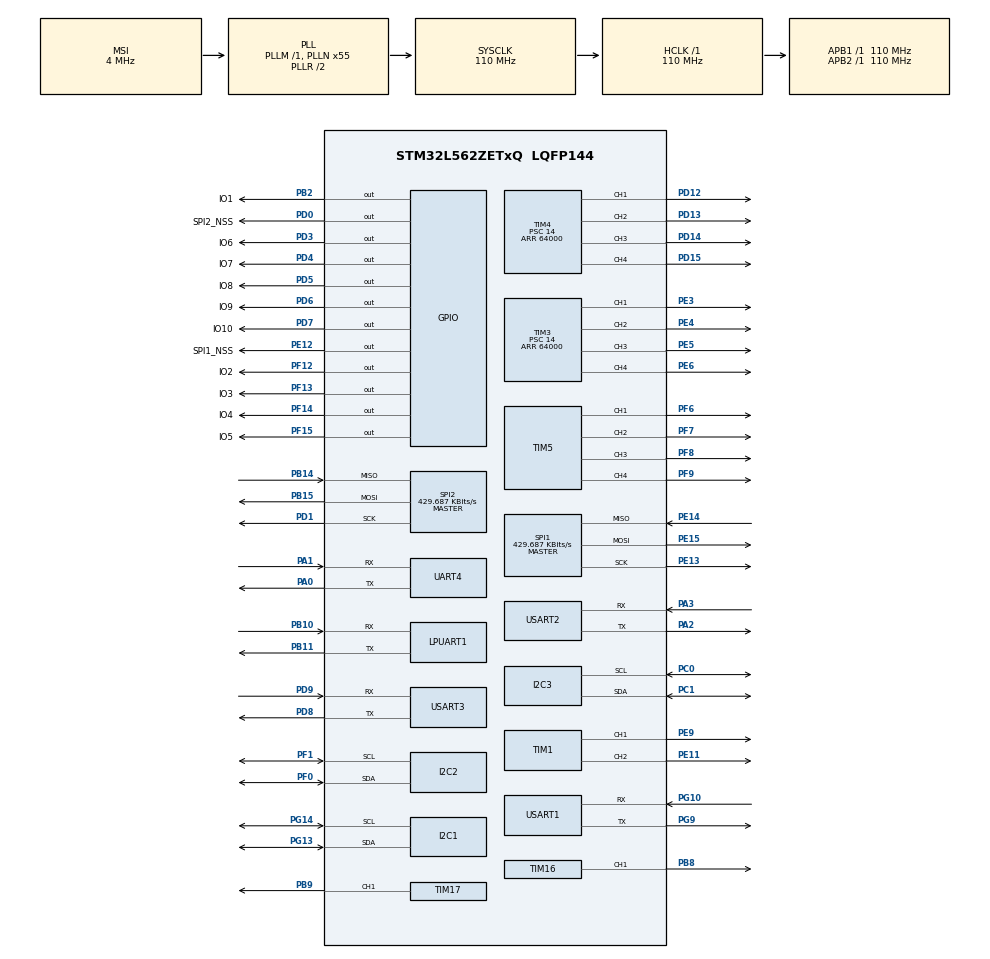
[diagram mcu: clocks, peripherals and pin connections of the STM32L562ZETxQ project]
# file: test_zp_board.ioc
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I2C1.Timing=0x60514452
I2C2.Timing=0x60514452
I2C3.Timing=0x60514452
Mcu.Family=STM32L5
Mcu.Name=STM32L562ZETxQ
Mcu.Package=LQFP144
NVIC.PriorityGroup=NVIC_PRIORITYGROUP_3
PA0.Mode=Asynchronous
PA0.Signal=UART4_TX
PA1.Mode=Asynchronous
PA1.Signal=UART4_RX
PA13\ (JTMS/SWDIO).Mode=Trace_Asynchronous_SW
PA13\ (JTMS/SWDIO).Signal=DEBUG_JTMS-SWDIO
PA14\ (JTCK/SWCLK).Mode=Trace_Asynchronous_SW
PA14\ (JTCK/SWCLK).Signal=DEBUG_JTCK-SWCLK
PA2.Mode=Asynchronous
PA2.Signal=USART2_TX
PA3.Mode=Asynchronous
PA3.Signal=USART2_RX
PB10.Mode=Asynchronous
PB10.Signal=LPUART1_RX
PB11.Mode=Asynchronous
PB11.Signal=LPUART1_TX
PB14.Mode=Full_Duplex_Master
PB14.Signal=SPI2_MISO
PB15.Mode=Full_Duplex_Master
PB15.Signal=SPI2_MOSI
PB2.GPIO_Label=IO1
PB2.PinState=GPIO_PIN_RESET
PB2.Signal=GPIO_Output
PB3\ (JTDO/TRACESWO).Mode=Trace_Asynchronous_SW
PB3\ (JTDO/TRACESWO).Signal=DEBUG_JTDO-SWO
PB8.Signal=S_TIM16_CH1
PB9.Signal=S_TIM17_CH1
PC0.Mode=I2C
PC0.Signal=I2C3_SCL
PC1.Mode=I2C
PC1.Signal=I2C3_SDA
PD0.GPIO_Label=SPI2_NSS
PD0.PinState=GPIO_PIN_SET
PD0.Signal=GPIO_Output
PD1.Mode=Full_Duplex_Master
PD1.Signal=SPI2_SCK
PD12.Signal=S_TIM4_CH1
PD13.Signal=S_TIM4_CH2
PD14.Signal=S_TIM4_CH3
PD15.Signal=S_TIM4_CH4
PD3.GPIO_Label=IO6
PD3.Signal=GPIO_Output
PD4.GPIO_Label=IO7
PD4.Signal=GPIO_Output
PD5.GPIO_Label=IO8
PD5.Signal=GPIO_Output
PD6.GPIO_Label=IO9
PD6.Signal=GPIO_Output
PD7.GPIO_Label=IO10
PD7.Signal=GPIO_Output
PD8.Mode=Asynchronous
PD8.Signal=USART3_TX
PD9.Mode=Asynchronous
PD9.Signal=USART3_RX
PE11.Signal=S_TIM1_CH2
PE12.GPIO_Label=SPI1_NSS
PE12.PinState=GPIO_PIN_SET
PE12.Signal=GPIO_Output
PE13.Mode=Full_Duplex_Master
PE13.Signal=SPI1_SCK
PE14.Mode=Full_Duplex_Master
PE14.Signal=SPI1_MISO
PE15.Mode=Full_Duplex_Master
PE15.Signal=SPI1_MOSI
PE3.Signal=S_TIM3_CH1
PE4.Signal=S_TIM3_CH2
PE5.Signal=S_TIM3_CH3
PE6.Signal=S_TIM3_CH4
PE9.Signal=S_TIM1_CH1
PF0.Mode=I2C
PF0.Signal=I2C2_SDA
PF1.Mode=I2C
PF1.Signal=I2C2_SCL
PF12.GPIO_Label=IO2
PF12.Signal=GPIO_Output
PF13.GPIO_Label=IO3
PF13.GPIO_ModeDefaultOutputPP=GPIO_MODE_OUTPUT_PP
PF13.GPIO_Speed=GPIO_SPEED_FREQ_LOW
PF13.Signal=GPIO_Output
PF14.GPIO_Label=IO4
PF14.Signal=GPIO_Output
PF15.GPIO_Label=IO5
PF15.Signal=GPIO_Output
PF6.Signal=S_TIM5_CH1
PF7.Signal=S_TIM5_CH2
PF8.Signal=S_TIM5_CH3
PF9.Signal=S_TIM5_CH4
PG10.Mode=Asynchronous
PG10.Signal=USART1_RX
PG13.Mode=I2C
PG13.Signal=I2C1_SDA
PG14.Mode=I2C
PG14.Signal=I2C1_SCL
PG9.Mode=Asynchronous
PG9.Signal=USART1_TX
PH0-OSC_IN\ (PH0).Mode=HSE-External-Oscillator
PH0-OSC_IN\ (PH0).Signal=RCC_OSC_IN
PH1-OSC_OUT\ (PH1).Mode=HSE-External-Oscillator
PH1-OSC_OUT\ (PH1).Signal=RCC_OSC_OUT
ProjectManager.HeapSize=0x200
ProjectManager.StackSize=0x400
ProjectManager.TargetToolchain=STM32CubeIDE
RCC.AHBFreq_Value=110000000
RCC.APB1Freq_Value=110000000
RCC.APB1TimFreq_Value=110000000
RCC.APB2Freq_Value=110000000
RCC.APB2TimFreq_Value=110000000
RCC.CortexFreq_Value=110000000
RCC.HCLKFreq_Value=110000000
RCC.HSE_VALUE=16000000
RCC.HSI48_VALUE=48000000
RCC.HSI_VALUE=16000000
RCC.LSE_VALUE=32768
RCC.MSI_VALUE=4000000
RCC.PLLN=55
RCC.SYSCLKFreq_VALUE=110000000
RCC.SYSCLKSource=RCC_SYSCLKSOURCE_PLLCLK
RCC.VCOOutputFreq_Value=220000000
SH.S_TIM16_CH1.0=TIM16_CH1,PWM Generation1 CH1
SH.S_TIM17_CH1.0=TIM17_CH1,PWM Generation1 CH1
SH.S_TIM1_CH1.0=TIM1_CH1,PWM Generation1 CH1
SH.S_TIM1_CH2.0=TIM1_CH2,PWM Generation2 CH2
SH.S_TIM3_CH1.0=TIM3_CH1,PWM Generation1 CH1
SH.S_TIM3_CH2.0=TIM3_CH2,PWM Generation2 CH2
SH.S_TIM3_CH3.0=TIM3_CH3,PWM Generation3 CH3
SH.S_TIM3_CH4.0=TIM3_CH4,PWM Generation4 CH4
SH.S_TIM4_CH1.0=TIM4_CH1,PWM Generation1 CH1
SH.S_TIM4_CH2.0=TIM4_CH2,PWM Generation2 CH2
SH.S_TIM4_CH3.0=TIM4_CH3,PWM Generation3 CH3
SH.S_TIM4_CH4.0=TIM4_CH4,PWM Generation4 CH4
SH.S_TIM5_CH1.0=TIM5_CH1,PWM Generation1 CH1
SH.S_TIM5_CH2.0=TIM5_CH2,PWM Generation2 CH2
SH.S_TIM5_CH3.0=TIM5_CH3,PWM Generation3 CH3
SH.S_TIM5_CH4.0=TIM5_CH4,Forced Output4 CH4
SPI1.BaudRatePrescaler=SPI_BAUDRATEPRESCALER_256
SPI1.CalculateBaudRate=429.687 KBits/s
SPI1.DataSize=SPI_DATASIZE_8BIT
SPI1.Direction=SPI_DIRECTION_2LINES
SPI1.Mode=SPI_MODE_MASTER
SPI1.VirtualType=VM_MASTER
SPI2.BaudRatePrescaler=SPI_BAUDRATEPRESCALER_256
SPI2.CalculateBaudRate=429.687 KBits/s
SPI2.DataSize=SPI_DATASIZE_8BIT
SPI2.Direction=SPI_DIRECTION_2LINES
SPI2.Mode=SPI_MODE_MASTER
SPI2.VirtualType=VM_MASTER
TIM1.Channel-PWM\ Generation1\ CH1=TIM_CHANNEL_1
TIM1.Channel-PWM\ Generation2\ CH2=TIM_CHANNEL_2
TIM16.Channel=TIM_CHANNEL_1
TIM17.Channel=TIM_CHANNEL_1
TIM3.Channel-PWM\ Generation1\ CH1=TIM_CHANNEL_1
TIM3.Channel-PWM\ Generation2\ CH2=TIM_CHANNEL_2
TIM3.Channel-PWM\ Generation3\ CH3=TIM_CHANNEL_3
TIM3.Channel-PWM\ Generation4\ CH4=TIM_CHANNEL_4
TIM3.Period=64000
TIM3.Prescaler=14
TIM4.Channel-PWM\ Generation1\ CH1=TIM_CHANNEL_1
TIM4.Channel-PWM\ Generation2\ CH2=TIM_CHANNEL_2
TIM4.Channel-PWM\ Generation3\ CH3=TIM_CHANNEL_3
TIM4.Channel-PWM\ Generation4\ CH4=TIM_CHANNEL_4
TIM4.Period=64000
TIM4.Prescaler=14
TIM5.Channel-Forced\ Output4\ CH4=TIM_CHANNEL_4
TIM5.Channel-PWM\ Generation1\ CH1=TIM_CHANNEL_1
TIM5.Channel-PWM\ Generation2\ CH2=TIM_CHANNEL_2
TIM5.Channel-PWM\ Generation3\ CH3=TIM_CHANNEL_3
USART1.VirtualMode-Asynchronous=VM_ASYNC
USART2.VirtualMode-Asynchronous=VM_ASYNC
USART3.VirtualMode-Asynchronous=VM_ASYNC
VP_PWR_VS_DBSignals.Mode=DisableDeadBatterySignals
VP_PWR_VS_SECSignals.Mode=Security/Privilege
VP_TIM16_VS_ClockSourceINT.Mode=Enable_Timer
VP_TIM17_VS_ClockSourceINT.Mode=Enable_Timer
VP_TIM1_VS_ClockSourceINT.Mode=Internal
VP_TIM3_VS_ClockSourceINT.Mode=Internal
VP_TIM4_VS_ClockSourceINT.Mode=Internal
VP_TIM5_VS_ClockSourceINT.Mode=Internal
board=custom

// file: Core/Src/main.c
/* USER CODE BEGIN Header */
/**
  ******************************************************************************
  * @file           : main.c
  * @brief          : Main program body
  ******************************************************************************
  * @attention
  *
  * Copyright (c) 2025 STMicroelectronics.
  * All rights reserved.
  *
  * This software is licensed under terms that can be found in the LICENSE file
  * in the root directory of this software component.
  * If no LICENSE file comes with this software, it is provided AS-IS.
  *
  ******************************************************************************
  */
/* USER CODE END Header */
#include "main.h"

/* USER CODE BEGIN Includes */
#include <stdio.h>
#include "test.h"
/* USER CODE END Includes */

I2C_HandleTypeDef hi2c1;
I2C_HandleTypeDef hi2c2;
I2C_HandleTypeDef hi2c3;

UART_HandleTypeDef hlpuart1;
UART_HandleTypeDef huart4;
UART_HandleTypeDef huart1;
UART_HandleTypeDef huart2;
UART_HandleTypeDef huart3;

SPI_HandleTypeDef hspi1;
SPI_HandleTypeDef hspi2;

TIM_HandleTypeDef htim1;
TIM_HandleTypeDef htim3;
TIM_HandleTypeDef htim4;
TIM_HandleTypeDef htim5;
TIM_HandleTypeDef htim16;
TIM_HandleTypeDef htim17;

void SystemClock_Config(void);
static void MX_GPIO_Init(void);
static void MX_TIM4_Init(void);
static void MX_TIM3_Init(void);
static void MX_SPI1_Init(void);
static void MX_SPI2_Init(void);
static void MX_I2C1_Init(void);
static void MX_I2C2_Init(void);
static void MX_I2C3_Init(void);
static void MX_UART4_Init(void);
static void MX_USART1_UART_Init(void);
static void MX_TIM1_Init(void);
static void MX_TIM5_Init(void);
static void MX_TIM16_Init(void);
static void MX_TIM17_Init(void);
static void MX_LPUART1_UART_Init(void);
static void MX_USART2_UART_Init(void);
static void MX_USART3_UART_Init(void);

int main(void)
{

  /* USER CODE BEGIN 1 */
  //uint32_t min_reload = __HAL_TIM_GET_AUTORELOAD(&htim4) * 0.05;
  /* USER CODE END 1 */

  /* MCU Configuration--------------------------------------------------------*/

  /* Reset of all peripherals, Initializes the Flash interface and the Systick. */
  HAL_Init();

  /* Configure the system clock */
  SystemClock_Config();

  /* Initialize all configured peripherals */
  MX_GPIO_Init();
  MX_TIM4_Init();
  MX_TIM3_Init();
  MX_SPI1_Init();
  MX_SPI2_Init();
  MX_I2C1_Init();
  MX_I2C2_Init();
  MX_I2C3_Init();
  MX_UART4_Init();
  MX_USART1_UART_Init();
  MX_TIM1_Init();
  MX_TIM5_Init();
  MX_TIM16_Init();
  MX_TIM17_Init();
  MX_LPUART1_UART_Init();
  MX_USART2_UART_Init();
  MX_USART3_UART_Init();
  /* USER CODE BEGIN 2 */
  //testGPIO();             //GPIO Testing
  //testTimers();           //Timer Testing
  /* USER CODE END 2 */

  /* Infinite loop */
  /* USER CODE BEGIN WHILE */
  while (1)
  {
    //testI2CTx(&hi2c1);    //I2C Testing (Transmit)
    //testI2CRx(&hi2c1);    //I2C Testing (Receive)
    //testSPI(&hspi2);      //SPI Testing
    testUART(&huart4);    //UART Testing
    HAL_Delay(1000);
    /* USER CODE END WHILE */

  }
}

void SystemClock_Config(void)
{
  RCC_OscInitTypeDef RCC_OscInitStruct = {0};
  RCC_ClkInitTypeDef RCC_ClkInitStruct = {0};

  /** Configure the main internal regulator output voltage
  */
  if (HAL_PWREx_ControlVoltageScaling(PWR_REGULATOR_VOLTAGE_SCALE0) != HAL_OK)
  {
    Error_Handler();
  }

  /** Initializes the RCC Oscillators according to the specified parameters
  * in the RCC_OscInitTypeDef structure.
  */
  RCC_OscInitStruct.OscillatorType = RCC_OSCILLATORTYPE_MSI;
  RCC_OscInitStruct.MSIState = RCC_MSI_ON;
  RCC_OscInitStruct.MSICalibrationValue = RCC_MSICALIBRATION_DEFAULT;
  RCC_OscInitStruct.MSIClockRange = RCC_MSIRANGE_6;
  RCC_OscInitStruct.PLL.PLLState = RCC_PLL_ON;
  RCC_OscInitStruct.PLL.PLLSource = RCC_PLLSOURCE_MSI;
  RCC_OscInitStruct.PLL.PLLM = 1;
  RCC_OscInitStruct.PLL.PLLN = 55;
  RCC_OscInitStruct.PLL.PLLP = RCC_PLLP_DIV7;
  RCC_OscInitStruct.PLL.PLLQ = RCC_PLLQ_DIV2;
  RCC_OscInitStruct.PLL.PLLR = RCC_PLLR_DIV2;
  if (HAL_RCC_OscConfig(&RCC_OscInitStruct) != HAL_OK)
  {
    Error_Handler();
  }

  /** Initializes the CPU, AHB and APB buses clocks
  */
  RCC_ClkInitStruct.ClockType = RCC_CLOCKTYPE_HCLK|RCC_CLOCKTYPE_SYSCLK
                              |RCC_CLOCKTYPE_PCLK1|RCC_CLOCKTYPE_PCLK2;
  RCC_ClkInitStruct.SYSCLKSource = RCC_SYSCLKSOURCE_PLLCLK;
  RCC_ClkInitStruct.AHBCLKDivider = RCC_SYSCLK_DIV1;
  RCC_ClkInitStruct.APB1CLKDivider = RCC_HCLK_DIV1;
  RCC_ClkInitStruct.APB2CLKDivider = RCC_HCLK_DIV1;

  if (HAL_RCC_ClockConfig(&RCC_ClkInitStruct, FLASH_LATENCY_5) != HAL_OK)
  {
    Error_Handler();
  }
}

static void MX_I2C1_Init(void)
{

  hi2c1.Instance = I2C1;
  hi2c1.Init.Timing = 0x60514452;
  hi2c1.Init.OwnAddress1 = 0;
  hi2c1.Init.AddressingMode = I2C_ADDRESSINGMODE_7BIT;
  hi2c1.Init.DualAddressMode = I2C_DUALADDRESS_DISABLE;
  hi2c1.Init.OwnAddress2 = 0;
  hi2c1.Init.OwnAddress2Masks = I2C_OA2_NOMASK;
  hi2c1.Init.GeneralCallMode = I2C_GENERALCALL_DISABLE;
  hi2c1.Init.NoStretchMode = I2C_NOSTRETCH_DISABLE;
  if (HAL_I2C_Init(&hi2c1) != HAL_OK)
  {
    Error_Handler();
  }

  /** Configure Analogue filter
  */
  if (HAL_I2CEx_ConfigAnalogFilter(&hi2c1, I2C_ANALOGFILTER_ENABLE) != HAL_OK)
  {
    Error_Handler();
  }

  /** Configure Digital filter
  */
  if (HAL_I2CEx_ConfigDigitalFilter(&hi2c1, 0) != HAL_OK)
  {
    Error_Handler();
  }

}

static void MX_I2C2_Init(void)
{

  hi2c2.Instance = I2C2;
  hi2c2.Init.Timing = 0x60514452;
  hi2c2.Init.OwnAddress1 = 0;
  hi2c2.Init.AddressingMode = I2C_ADDRESSINGMODE_7BIT;
  hi2c2.Init.DualAddressMode = I2C_DUALADDRESS_DISABLE;
  hi2c2.Init.OwnAddress2 = 0;
  hi2c2.Init.OwnAddress2Masks = I2C_OA2_NOMASK;
  hi2c2.Init.GeneralCallMode = I2C_GENERALCALL_DISABLE;
  hi2c2.Init.NoStretchMode = I2C_NOSTRETCH_DISABLE;
  if (HAL_I2C_Init(&hi2c2) != HAL_OK)
  {
    Error_Handler();
  }

  /** Configure Analogue filter
  */
  if (HAL_I2CEx_ConfigAnalogFilter(&hi2c2, I2C_ANALOGFILTER_ENABLE) != HAL_OK)
  {
    Error_Handler();
  }

  /** Configure Digital filter
  */
  if (HAL_I2CEx_ConfigDigitalFilter(&hi2c2, 0) != HAL_OK)
  {
    Error_Handler();
  }

}

static void MX_I2C3_Init(void)
{

  hi2c3.Instance = I2C3;
  hi2c3.Init.Timing = 0x60514452;
  hi2c3.Init.OwnAddress1 = 0;
  hi2c3.Init.AddressingMode = I2C_ADDRESSINGMODE_7BIT;
  hi2c3.Init.DualAddressMode = I2C_DUALADDRESS_DISABLE;
  hi2c3.Init.OwnAddress2 = 0;
  hi2c3.Init.OwnAddress2Masks = I2C_OA2_NOMASK;
  hi2c3.Init.GeneralCallMode = I2C_GENERALCALL_DISABLE;
  hi2c3.Init.NoStretchMode = I2C_NOSTRETCH_DISABLE;
  if (HAL_I2C_Init(&hi2c3) != HAL_OK)
  {
    Error_Handler();
  }

  /** Configure Analogue filter
  */
  if (HAL_I2CEx_ConfigAnalogFilter(&hi2c3, I2C_ANALOGFILTER_ENABLE) != HAL_OK)
  {
    Error_Handler();
  }

  /** Configure Digital filter
  */
  if (HAL_I2CEx_ConfigDigitalFilter(&hi2c3, 0) != HAL_OK)
  {
    Error_Handler();
  }

}

static void MX_LPUART1_UART_Init(void)
{

  hlpuart1.Instance = LPUART1;
  hlpuart1.Init.BaudRate = 209700;
  hlpuart1.Init.WordLength = UART_WORDLENGTH_8B;
  hlpuart1.Init.StopBits = UART_STOPBITS_1;
  hlpuart1.Init.Parity = UART_PARITY_NONE;
  hlpuart1.Init.Mode = UART_MODE_TX_RX;
  hlpuart1.Init.HwFlowCtl = UART_HWCONTROL_NONE;
  hlpuart1.Init.OneBitSampling = UART_ONE_BIT_SAMPLE_DISABLE;
  hlpuart1.Init.ClockPrescaler = UART_PRESCALER_DIV1;
  hlpuart1.AdvancedInit.AdvFeatureInit = UART_ADVFEATURE_NO_INIT;
  hlpuart1.FifoMode = UART_FIFOMODE_DISABLE;
  if (HAL_UART_Init(&hlpuart1) != HAL_OK)
  {
    Error_Handler();
  }
  if (HAL_UARTEx_SetTxFifoThreshold(&hlpuart1, UART_TXFIFO_THRESHOLD_1_8) != HAL_OK)
  {
    Error_Handler();
  }
  if (HAL_UARTEx_SetRxFifoThreshold(&hlpuart1, UART_RXFIFO_THRESHOLD_1_8) != HAL_OK)
  {
    Error_Handler();
  }
  if (HAL_UARTEx_DisableFifoMode(&hlpuart1) != HAL_OK)
  {
    Error_Handler();
  }

}

static void MX_UART4_Init(void)
{

  huart4.Instance = UART4;
  huart4.Init.BaudRate = 115200;
  huart4.Init.WordLength = UART_WORDLENGTH_8B;
  huart4.Init.StopBits = UART_STOPBITS_1;
  huart4.Init.Parity = UART_PARITY_NONE;
  huart4.Init.Mode = UART_MODE_TX_RX;
  huart4.Init.HwFlowCtl = UART_HWCONTROL_NONE;
  huart4.Init.OverSampling = UART_OVERSAMPLING_16;
  huart4.Init.OneBitSampling = UART_ONE_BIT_SAMPLE_DISABLE;
  huart4.Init.ClockPrescaler = UART_PRESCALER_DIV1;
  huart4.AdvancedInit.AdvFeatureInit = UART_ADVFEATURE_NO_INIT;
  if (HAL_UART_Init(&huart4) != HAL_OK)
  {
    Error_Handler();
  }
  if (HAL_UARTEx_SetTxFifoThreshold(&huart4, UART_TXFIFO_THRESHOLD_1_8) != HAL_OK)
  {
    Error_Handler();
  }
  if (HAL_UARTEx_SetRxFifoThreshold(&huart4, UART_RXFIFO_THRESHOLD_1_8) != HAL_OK)
  {
    Error_Handler();
  }
  if (HAL_UARTEx_DisableFifoMode(&huart4) != HAL_OK)
  {
    Error_Handler();
  }

}

static void MX_USART1_UART_Init(void)
{

  huart1.Instance = USART1;
  huart1.Init.BaudRate = 115200;
  huart1.Init.WordLength = UART_WORDLENGTH_8B;
  huart1.Init.StopBits = UART_STOPBITS_1;
  huart1.Init.Parity = UART_PARITY_NONE;
  huart1.Init.Mode = UART_MODE_TX_RX;
  huart1.Init.HwFlowCtl = UART_HWCONTROL_NONE;
  huart1.Init.OverSampling = UART_OVERSAMPLING_16;
  huart1.Init.OneBitSampling = UART_ONE_BIT_SAMPLE_DISABLE;
  huart1.Init.ClockPrescaler = UART_PRESCALER_DIV1;
  huart1.AdvancedInit.AdvFeatureInit = UART_ADVFEATURE_NO_INIT;
  if (HAL_UART_Init(&huart1) != HAL_OK)
  {
    Error_Handler();
  }
  if (HAL_UARTEx_SetTxFifoThreshold(&huart1, UART_TXFIFO_THRESHOLD_1_8) != HAL_OK)
  {
    Error_Handler();
  }
  if (HAL_UARTEx_SetRxFifoThreshold(&huart1, UART_RXFIFO_THRESHOLD_1_8) != HAL_OK)
  {
    Error_Handler();
  }
  if (HAL_UARTEx_DisableFifoMode(&huart1) != HAL_OK)
  {
    Error_Handler();
  }

}

static void MX_USART2_UART_Init(void)
{

  huart2.Instance = USART2;
  huart2.Init.BaudRate = 115200;
  huart2.Init.WordLength = UART_WORDLENGTH_8B;
  huart2.Init.StopBits = UART_STOPBITS_1;
  huart2.Init.Parity = UART_PARITY_NONE;
  huart2.Init.Mode = UART_MODE_TX_RX;
  huart2.Init.HwFlowCtl = UART_HWCONTROL_NONE;
  huart2.Init.OverSampling = UART_OVERSAMPLING_16;
  huart2.Init.OneBitSampling = UART_ONE_BIT_SAMPLE_DISABLE;
  huart2.Init.ClockPrescaler = UART_PRESCALER_DIV1;
  huart2.AdvancedInit.AdvFeatureInit = UART_ADVFEATURE_NO_INIT;
  if (HAL_UART_Init(&huart2) != HAL_OK)
  {
    Error_Handler();
  }
  if (HAL_UARTEx_SetTxFifoThreshold(&huart2, UART_TXFIFO_THRESHOLD_1_8) != HAL_OK)
  {
    Error_Handler();
  }
  if (HAL_UARTEx_SetRxFifoThreshold(&huart2, UART_RXFIFO_THRESHOLD_1_8) != HAL_OK)
  {
    Error_Handler();
  }
  if (HAL_UARTEx_DisableFifoMode(&huart2) != HAL_OK)
  {
    Error_Handler();
  }

}

static void MX_USART3_UART_Init(void)
{

  huart3.Instance = USART3;
  huart3.Init.BaudRate = 115200;
  huart3.Init.WordLength = UART_WORDLENGTH_8B;
  huart3.Init.StopBits = UART_STOPBITS_1;
  huart3.Init.Parity = UART_PARITY_NONE;
  huart3.Init.Mode = UART_MODE_TX_RX;
  huart3.Init.HwFlowCtl = UART_HWCONTROL_NONE;
  huart3.Init.OverSampling = UART_OVERSAMPLING_16;
  huart3.Init.OneBitSampling = UART_ONE_BIT_SAMPLE_DISABLE;
  huart3.Init.ClockPrescaler = UART_PRESCALER_DIV1;
  huart3.AdvancedInit.AdvFeatureInit = UART_ADVFEATURE_NO_INIT;
  if (HAL_UART_Init(&huart3) != HAL_OK)
  {
    Error_Handler();
  }
  if (HAL_UARTEx_SetTxFifoThreshold(&huart3, UART_TXFIFO_THRESHOLD_1_8) != HAL_OK)
  {
    Error_Handler();
  }
  if (HAL_UARTEx_SetRxFifoThreshold(&huart3, UART_RXFIFO_THRESHOLD_1_8) != HAL_OK)
  {
    Error_Handler();
  }
  if (HAL_UARTEx_DisableFifoMode(&huart3) != HAL_OK)
  {
    Error_Handler();
  }

}

static void MX_SPI1_Init(void)
{

  /* SPI1 parameter configuration*/
  hspi1.Instance = SPI1;
  hspi1.Init.Mode = SPI_MODE_MASTER;
  hspi1.Init.Direction = SPI_DIRECTION_2LINES;
  hspi1.Init.DataSize = SPI_DATASIZE_8BIT;
  hspi1.Init.CLKPolarity = SPI_POLARITY_LOW;
  hspi1.Init.CLKPhase = SPI_PHASE_1EDGE;
  hspi1.Init.NSS = SPI_NSS_SOFT;
  hspi1.Init.BaudRatePrescaler = SPI_BAUDRATEPRESCALER_256;
  hspi1.Init.FirstBit = SPI_FIRSTBIT_MSB;
  hspi1.Init.TIMode = SPI_TIMODE_DISABLE;
  hspi1.Init.CRCCalculation = SPI_CRCCALCULATION_DISABLE;
  hspi1.Init.CRCPolynomial = 7;
  hspi1.Init.CRCLength = SPI_CRC_LENGTH_DATASIZE;
  hspi1.Init.NSSPMode = SPI_NSS_PULSE_ENABLE;
  if (HAL_SPI_Init(&hspi1) != HAL_OK)
  {
    Error_Handler();
  }

}

static void MX_SPI2_Init(void)
{

  /* SPI2 parameter configuration*/
  hspi2.Instance = SPI2;
  hspi2.Init.Mode = SPI_MODE_MASTER;
  hspi2.Init.Direction = SPI_DIRECTION_2LINES;
  hspi2.Init.DataSize = SPI_DATASIZE_8BIT;
  hspi2.Init.CLKPolarity = SPI_POLARITY_LOW;
  hspi2.Init.CLKPhase = SPI_PHASE_1EDGE;
  hspi2.Init.NSS = SPI_NSS_SOFT;
  hspi2.Init.BaudRatePrescaler = SPI_BAUDRATEPRESCALER_256;
  hspi2.Init.FirstBit = SPI_FIRSTBIT_MSB;
  hspi2.Init.TIMode = SPI_TIMODE_DISABLE;
  hspi2.Init.CRCCalculation = SPI_CRCCALCULATION_DISABLE;
  hspi2.Init.CRCPolynomial = 7;
  hspi2.Init.CRCLength = SPI_CRC_LENGTH_DATASIZE;
  hspi2.Init.NSSPMode = SPI_NSS_PULSE_ENABLE;
  if (HAL_SPI_Init(&hspi2) != HAL_OK)
  {
    Error_Handler();
  }

}

static void MX_TIM1_Init(void)
{

  TIM_ClockConfigTypeDef sClockSourceConfig = {0};
  TIM_MasterConfigTypeDef sMasterConfig = {0};
  TIM_OC_InitTypeDef sConfigOC = {0};
  TIM_BreakDeadTimeConfigTypeDef sBreakDeadTimeConfig = {0};

  htim1.Instance = TIM1;
  htim1.Init.Prescaler = 0;
  htim1.Init.CounterMode = TIM_COUNTERMODE_UP;
  htim1.Init.Period = 65535;
  htim1.Init.ClockDivision = TIM_CLOCKDIVISION_DIV1;
  htim1.Init.RepetitionCounter = 0;
  htim1.Init.AutoReloadPreload = TIM_AUTORELOAD_PRELOAD_DISABLE;
  if (HAL_TIM_Base_Init(&htim1) != HAL_OK)
  {
    Error_Handler();
  }
  sClockSourceConfig.ClockSource = TIM_CLOCKSOURCE_INTERNAL;
  if (HAL_TIM_ConfigClockSource(&htim1, &sClockSourceConfig) != HAL_OK)
  {
    Error_Handler();
  }
  if (HAL_TIM_PWM_Init(&htim1) != HAL_OK)
  {
    Error_Handler();
  }
  sMasterConfig.MasterOutputTrigger = TIM_TRGO_RESET;
  sMasterConfig.MasterOutputTrigger2 = TIM_TRGO2_RESET;
  sMasterConfig.MasterSlaveMode = TIM_MASTERSLAVEMODE_DISABLE;
  if (HAL_TIMEx_MasterConfigSynchronization(&htim1, &sMasterConfig) != HAL_OK)
  {
    Error_Handler();
  }
  sConfigOC.OCMode = TIM_OCMODE_PWM1;
  sConfigOC.Pulse = 0;
  sConfigOC.OCPolarity = TIM_OCPOLARITY_HIGH;
  sConfigOC.OCNPolarity = TIM_OCNPOLARITY_HIGH;
  sConfigOC.OCFastMode = TIM_OCFAST_DISABLE;
  sConfigOC.OCIdleState = TIM_OCIDLESTATE_RESET;
  sConfigOC.OCNIdleState = TIM_OCNIDLESTATE_RESET;
  if (HAL_TIM_PWM_ConfigChannel(&htim1, &sConfigOC, TIM_CHANNEL_1) != HAL_OK)
  {
    Error_Handler();
  }
  if (HAL_TIM_PWM_ConfigChannel(&htim1, &sConfigOC, TIM_CHANNEL_2) != HAL_OK)
  {
    Error_Handler();
  }
  sBreakDeadTimeConfig.OffStateRunMode = TIM_OSSR_DISABLE;
  sBreakDeadTimeConfig.OffStateIDLEMode = TIM_OSSI_DISABLE;
  sBreakDeadTimeConfig.LockLevel = TIM_LOCKLEVEL_OFF;
  sBreakDeadTimeConfig.DeadTime = 0;
  sBreakDeadTimeConfig.BreakState = TIM_BREAK_DISABLE;
  sBreakDeadTimeConfig.BreakPolarity = TIM_BREAKPOLARITY_HIGH;
  sBreakDeadTimeConfig.BreakFilter = 0;
  sBreakDeadTimeConfig.BreakAFMode = TIM_BREAK_AFMODE_INPUT;
  sBreakDeadTimeConfig.Break2State = TIM_BREAK2_DISABLE;
  sBreakDeadTimeConfig.Break2Polarity = TIM_BREAK2POLARITY_HIGH;
  sBreakDeadTimeConfig.Break2Filter = 0;
  sBreakDeadTimeConfig.Break2AFMode = TIM_BREAK_AFMODE_INPUT;
  sBreakDeadTimeConfig.AutomaticOutput = TIM_AUTOMATICOUTPUT_DISABLE;
  if (HAL_TIMEx_ConfigBreakDeadTime(&htim1, &sBreakDeadTimeConfig) != HAL_OK)
  {
    Error_Handler();
  }
  HAL_TIM_MspPostInit(&htim1);

}

static void MX_TIM3_Init(void)
{

  TIM_ClockConfigTypeDef sClockSourceConfig = {0};
  TIM_MasterConfigTypeDef sMasterConfig = {0};
  TIM_OC_InitTypeDef sConfigOC = {0};

  htim3.Instance = TIM3;
  htim3.Init.Prescaler = 14;
  htim3.Init.CounterMode = TIM_COUNTERMODE_UP;
  htim3.Init.Period = 64000;
  htim3.Init.ClockDivision = TIM_CLOCKDIVISION_DIV1;
  htim3.Init.AutoReloadPreload = TIM_AUTORELOAD_PRELOAD_DISABLE;
  if (HAL_TIM_Base_Init(&htim3) != HAL_OK)
  {
    Error_Handler();
  }
  sClockSourceConfig.ClockSource = TIM_CLOCKSOURCE_INTERNAL;
  if (HAL_TIM_ConfigClockSource(&htim3, &sClockSourceConfig) != HAL_OK)
  {
    Error_Handler();
  }
  if (HAL_TIM_PWM_Init(&htim3) != HAL_OK)
  {
    Error_Handler();
  }
  sMasterConfig.MasterOutputTrigger = TIM_TRGO_RESET;
  sMasterConfig.MasterSlaveMode = TIM_MASTERSLAVEMODE_DISABLE;
  if (HAL_TIMEx_MasterConfigSynchronization(&htim3, &sMasterConfig) != HAL_OK)
  {
    Error_Handler();
  }
  sConfigOC.OCMode = TIM_OCMODE_PWM1;
  sConfigOC.Pulse = 0;
  sConfigOC.OCPolarity = TIM_OCPOLARITY_HIGH;
  sConfigOC.OCFastMode = TIM_OCFAST_DISABLE;
  if (HAL_TIM_PWM_ConfigChannel(&htim3, &sConfigOC, TIM_CHANNEL_1) != HAL_OK)
  {
    Error_Handler();
  }
  if (HAL_TIM_PWM_ConfigChannel(&htim3, &sConfigOC, TIM_CHANNEL_2) != HAL_OK)
  {
    Error_Handler();
  }
  if (HAL_TIM_PWM_ConfigChannel(&htim3, &sConfigOC, TIM_CHANNEL_3) != HAL_OK)
  {
    Error_Handler();
  }
  if (HAL_TIM_PWM_ConfigChannel(&htim3, &sConfigOC, TIM_CHANNEL_4) != HAL_OK)
  {
    Error_Handler();
  }
  HAL_TIM_MspPostInit(&htim3);

}

static void MX_TIM4_Init(void)
{

  TIM_ClockConfigTypeDef sClockSourceConfig = {0};
  TIM_MasterConfigTypeDef sMasterConfig = {0};
  TIM_OC_InitTypeDef sConfigOC = {0};

  htim4.Instance = TIM4;
  htim4.Init.Prescaler = 14;
  htim4.Init.CounterMode = TIM_COUNTERMODE_UP;
  htim4.Init.Period = 64000;
  htim4.Init.ClockDivision = TIM_CLOCKDIVISION_DIV1;
  htim4.Init.AutoReloadPreload = TIM_AUTORELOAD_PRELOAD_DISABLE;
  if (HAL_TIM_Base_Init(&htim4) != HAL_OK)
  {
    Error_Handler();
  }
  sClockSourceConfig.ClockSource = TIM_CLOCKSOURCE_INTERNAL;
  if (HAL_TIM_ConfigClockSource(&htim4, &sClockSourceConfig) != HAL_OK)
  {
    Error_Handler();
  }
  if (HAL_TIM_PWM_Init(&htim4) != HAL_OK)
  {
    Error_Handler();
  }
  sMasterConfig.MasterOutputTrigger = TIM_TRGO_RESET;
  sMasterConfig.MasterSlaveMode = TIM_MASTERSLAVEMODE_DISABLE;
  if (HAL_TIMEx_MasterConfigSynchronization(&htim4, &sMasterConfig) != HAL_OK)
  {
    Error_Handler();
  }
  sConfigOC.OCMode = TIM_OCMODE_PWM1;
  sConfigOC.Pulse = 0;
  sConfigOC.OCPolarity = TIM_OCPOLARITY_HIGH;
  sConfigOC.OCFastMode = TIM_OCFAST_DISABLE;
  if (HAL_TIM_PWM_ConfigChannel(&htim4, &sConfigOC, TIM_CHANNEL_1) != HAL_OK)
  {
    Error_Handler();
  }
  if (HAL_TIM_PWM_ConfigChannel(&htim4, &sConfigOC, TIM_CHANNEL_2) != HAL_OK)
  {
    Error_Handler();
  }
  if (HAL_TIM_PWM_ConfigChannel(&htim4, &sConfigOC, TIM_CHANNEL_3) != HAL_OK)
  {
    Error_Handler();
  }
  if (HAL_TIM_PWM_ConfigChannel(&htim4, &sConfigOC, TIM_CHANNEL_4) != HAL_OK)
  {
    Error_Handler();
  }
  HAL_TIM_MspPostInit(&htim4);

}

static void MX_TIM5_Init(void)
{

  TIM_ClockConfigTypeDef sClockSourceConfig = {0};
  TIM_MasterConfigTypeDef sMasterConfig = {0};
  TIM_OC_InitTypeDef sConfigOC = {0};

  htim5.Instance = TIM5;
  htim5.Init.Prescaler = 0;
  htim5.Init.CounterMode = TIM_COUNTERMODE_UP;
  htim5.Init.Period = 4294967295;
  htim5.Init.ClockDivision = TIM_CLOCKDIVISION_DIV1;
  htim5.Init.AutoReloadPreload = TIM_AUTORELOAD_PRELOAD_DISABLE;
  if (HAL_TIM_Base_Init(&htim5) != HAL_OK)
  {
    Error_Handler();
  }
  sClockSourceConfig.ClockSource = TIM_CLOCKSOURCE_INTERNAL;
  if (HAL_TIM_ConfigClockSource(&htim5, &sClockSourceConfig) != HAL_OK)
  {
    Error_Handler();
  }
  if (HAL_TIM_PWM_Init(&htim5) != HAL_OK)
  {
    Error_Handler();
  }
  if (HAL_TIM_OC_Init(&htim5) != HAL_OK)
  {
    Error_Handler();
  }
  sMasterConfig.MasterOutputTrigger = TIM_TRGO_RESET;
  sMasterConfig.MasterSlaveMode = TIM_MASTERSLAVEMODE_DISABLE;
  if (HAL_TIMEx_MasterConfigSynchronization(&htim5, &sMasterConfig) != HAL_OK)
  {
    Error_Handler();
  }
  sConfigOC.OCMode = TIM_OCMODE_PWM1;
  sConfigOC.Pulse = 0;
  sConfigOC.OCPolarity = TIM_OCPOLARITY_HIGH;
  sConfigOC.OCFastMode = TIM_OCFAST_DISABLE;
  if (HAL_TIM_PWM_ConfigChannel(&htim5, &sConfigOC, TIM_CHANNEL_1) != HAL_OK)
  {
    Error_Handler();
  }
  if (HAL_TIM_PWM_ConfigChannel(&htim5, &sConfigOC, TIM_CHANNEL_2) != HAL_OK)
  {
    Error_Handler();
  }
  if (HAL_TIM_PWM_ConfigChannel(&htim5, &sConfigOC, TIM_CHANNEL_3) != HAL_OK)
  {
    Error_Handler();
  }
  sConfigOC.OCMode = TIM_OCMODE_FORCED_ACTIVE;
  if (HAL_TIM_OC_ConfigChannel(&htim5, &sConfigOC, TIM_CHANNEL_4) != HAL_OK)
  {
    Error_Handler();
  }
  HAL_TIM_MspPostInit(&htim5);

}

static void MX_TIM16_Init(void)
{

  TIM_OC_InitTypeDef sConfigOC = {0};
  TIM_BreakDeadTimeConfigTypeDef sBreakDeadTimeConfig = {0};

  htim16.Instance = TIM16;
  htim16.Init.Prescaler = 0;
  htim16.Init.CounterMode = TIM_COUNTERMODE_UP;
  htim16.Init.Period = 65535;
  htim16.Init.ClockDivision = TIM_CLOCKDIVISION_DIV1;
  htim16.Init.RepetitionCounter = 0;
  htim16.Init.AutoReloadPreload = TIM_AUTORELOAD_PRELOAD_DISABLE;
  if (HAL_TIM_Base_Init(&htim16) != HAL_OK)
  {
    Error_Handler();
  }
  if (HAL_TIM_PWM_Init(&htim16) != HAL_OK)
  {
    Error_Handler();
  }
  sConfigOC.OCMode = TIM_OCMODE_PWM1;
  sConfigOC.Pulse = 0;
  sConfigOC.OCPolarity = TIM_OCPOLARITY_HIGH;
  sConfigOC.OCNPolarity = TIM_OCNPOLARITY_HIGH;
  sConfigOC.OCFastMode = TIM_OCFAST_DISABLE;
  sConfigOC.OCIdleState = TIM_OCIDLESTATE_RESET;
  sConfigOC.OCNIdleState = TIM_OCNIDLESTATE_RESET;
  if (HAL_TIM_PWM_ConfigChannel(&htim16, &sConfigOC, TIM_CHANNEL_1) != HAL_OK)
  {
    Error_Handler();
  }
  sBreakDeadTimeConfig.OffStateRunMode = TIM_OSSR_DISABLE;
  sBreakDeadTimeConfig.OffStateIDLEMode = TIM_OSSI_DISABLE;
  sBreakDeadTimeConfig.LockLevel = TIM_LOCKLEVEL_OFF;
  sBreakDeadTimeConfig.DeadTime = 0;
  sBreakDeadTimeConfig.BreakState = TIM_BREAK_DISABLE;
  sBreakDeadTimeConfig.BreakPolarity = TIM_BREAKPOLARITY_HIGH;
  sBreakDeadTimeConfig.BreakFilter = 0;
  sBreakDeadTimeConfig.AutomaticOutput = TIM_AUTOMATICOUTPUT_DISABLE;
  if (HAL_TIMEx_ConfigBreakDeadTime(&htim16, &sBreakDeadTimeConfig) != HAL_OK)
  {
    Error_Handler();
  }
  HAL_TIM_MspPostInit(&htim16);

}

static void MX_TIM17_Init(void)
{

  TIM_OC_InitTypeDef sConfigOC = {0};
  TIM_BreakDeadTimeConfigTypeDef sBreakDeadTimeConfig = {0};

  htim17.Instance = TIM17;
  htim17.Init.Prescaler = 0;
  htim17.Init.CounterMode = TIM_COUNTERMODE_UP;
  htim17.Init.Period = 65535;
  htim17.Init.ClockDivision = TIM_CLOCKDIVISION_DIV1;
  htim17.Init.RepetitionCounter = 0;
  htim17.Init.AutoReloadPreload = TIM_AUTORELOAD_PRELOAD_DISABLE;
  if (HAL_TIM_Base_Init(&htim17) != HAL_OK)
  {
    Error_Handler();
  }
  if (HAL_TIM_PWM_Init(&htim17) != HAL_OK)
  {
    Error_Handler();
  }
  sConfigOC.OCMode = TIM_OCMODE_PWM1;
  sConfigOC.Pulse = 0;
  sConfigOC.OCPolarity = TIM_OCPOLARITY_HIGH;
  sConfigOC.OCNPolarity = TIM_OCNPOLARITY_HIGH;
  sConfigOC.OCFastMode = TIM_OCFAST_DISABLE;
  sConfigOC.OCIdleState = TIM_OCIDLESTATE_RESET;
  sConfigOC.OCNIdleState = TIM_OCNIDLESTATE_RESET;
  if (HAL_TIM_PWM_ConfigChannel(&htim17, &sConfigOC, TIM_CHANNEL_1) != HAL_OK)
  {
    Error_Handler();
  }
  sBreakDeadTimeConfig.OffStateRunMode = TIM_OSSR_DISABLE;
  sBreakDeadTimeConfig.OffStateIDLEMode = TIM_OSSI_DISABLE;
  sBreakDeadTimeConfig.LockLevel = TIM_LOCKLEVEL_OFF;
  sBreakDeadTimeConfig.DeadTime = 0;
  sBreakDeadTimeConfig.BreakState = TIM_BREAK_DISABLE;
  sBreakDeadTimeConfig.BreakPolarity = TIM_BREAKPOLARITY_HIGH;
  sBreakDeadTimeConfig.BreakFilter = 0;
  sBreakDeadTimeConfig.AutomaticOutput = TIM_AUTOMATICOUTPUT_DISABLE;
  if (HAL_TIMEx_ConfigBreakDeadTime(&htim17, &sBreakDeadTimeConfig) != HAL_OK)
  {
    Error_Handler();
  }
  HAL_TIM_MspPostInit(&htim17);

}

static void MX_GPIO_Init(void)
{
  GPIO_InitTypeDef GPIO_InitStruct = {0};

  /* GPIO Ports Clock Enable */
  __HAL_RCC_GPIOE_CLK_ENABLE();
  __HAL_RCC_GPIOF_CLK_ENABLE();
  __HAL_RCC_GPIOH_CLK_ENABLE();
  __HAL_RCC_GPIOC_CLK_ENABLE();
  __HAL_RCC_GPIOA_CLK_ENABLE();
  __HAL_RCC_GPIOB_CLK_ENABLE();
  __HAL_RCC_GPIOD_CLK_ENABLE();
  __HAL_RCC_GPIOG_CLK_ENABLE();
  HAL_PWREx_EnableVddIO2();

  /*Configure GPIO pin Output Level */
  HAL_GPIO_WritePin(IO1_GPIO_Port, IO1_Pin, GPIO_PIN_RESET);

  /*Configure GPIO pin Output Level */
  HAL_GPIO_WritePin(GPIOF, IO2_Pin|IO3_Pin|IO4_Pin|IO5_Pin, GPIO_PIN_RESET);

  /*Configure GPIO pin Output Level */
  HAL_GPIO_WritePin(SPI1_NSS_GPIO_Port, SPI1_NSS_Pin, GPIO_PIN_SET);

  /*Configure GPIO pin Output Level */
  HAL_GPIO_WritePin(SPI2_NSS_GPIO_Port, SPI2_NSS_Pin, GPIO_PIN_SET);

  /*Configure GPIO pin Output Level */
  HAL_GPIO_WritePin(GPIOD, IO6_Pin|IO7_Pin|IO8_Pin|IO9_Pin
                          |IO10_Pin, GPIO_PIN_RESET);

  /*Configure GPIO pin : IO1_Pin */
  GPIO_InitStruct.Pin = IO1_Pin;
  GPIO_InitStruct.Mode = GPIO_MODE_OUTPUT_PP;
  GPIO_InitStruct.Pull = GPIO_NOPULL;
  GPIO_InitStruct.Speed = GPIO_SPEED_FREQ_LOW;
  HAL_GPIO_Init(IO1_GPIO_Port, &GPIO_InitStruct);

  /*Configure GPIO pins : IO2_Pin IO3_Pin IO4_Pin IO5_Pin */
  GPIO_InitStruct.Pin = IO2_Pin|IO3_Pin|IO4_Pin|IO5_Pin;
  GPIO_InitStruct.Mode = GPIO_MODE_OUTPUT_PP;
  GPIO_InitStruct.Pull = GPIO_NOPULL;
  GPIO_InitStruct.Speed = GPIO_SPEED_FREQ_LOW;
  HAL_GPIO_Init(GPIOF, &GPIO_InitStruct);

  /*Configure GPIO pin : SPI1_NSS_Pin */
  GPIO_InitStruct.Pin = SPI1_NSS_Pin;
  GPIO_InitStruct.Mode = GPIO_MODE_OUTPUT_PP;
  GPIO_InitStruct.Pull = GPIO_NOPULL;
  GPIO_InitStruct.Speed = GPIO_SPEED_FREQ_LOW;
  HAL_GPIO_Init(SPI1_NSS_GPIO_Port, &GPIO_InitStruct);

  /*Configure GPIO pins : SPI2_NSS_Pin IO6_Pin IO7_Pin IO8_Pin
                           IO9_Pin IO10_Pin */
  GPIO_InitStruct.Pin = SPI2_NSS_Pin|IO6_Pin|IO7_Pin|IO8_Pin
                          |IO9_Pin|IO10_Pin;
  GPIO_InitStruct.Mode = GPIO_MODE_OUTPUT_PP;
  GPIO_InitStruct.Pull = GPIO_NOPULL;
  GPIO_InitStruct.Speed = GPIO_SPEED_FREQ_LOW;
  HAL_GPIO_Init(GPIOD, &GPIO_InitStruct);

}

/* USER CODE BEGIN 4 */
int __io_putchar(int ch)
{
  return ITM_SendChar(ch);
}
/* USER CODE END 4 */

void Error_Handler(void)
{
  __disable_irq();
  while (1)
  {
  }
}
